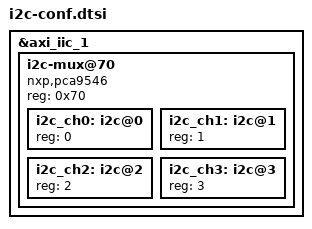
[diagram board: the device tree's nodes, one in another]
/ {
};

&axi_iic_1 {
    status = "okay";

    i2c-mux@70 {
        compatible = "nxp,pca9546";
        reg = <0x70>;
        #address-cells = <1>;
        #size-cells = <0>;

        i2c_ch0: i2c@0 {
            #address-cells = <1>;
            #size-cells = <0>;
            reg = <0>;
        };

        i2c_ch1: i2c@1 {
            #address-cells = <1>;
            #size-cells = <0>;
            reg = <1>;
        };

        i2c_ch2: i2c@2 {
            #address-cells = <1>;
            #size-cells = <0>;
            reg = <2>;
        };

        i2c_ch3: i2c@3 {
            #address-cells = <1>;
            #size-cells = <0>;
            reg = <3>;
        };
    };
};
